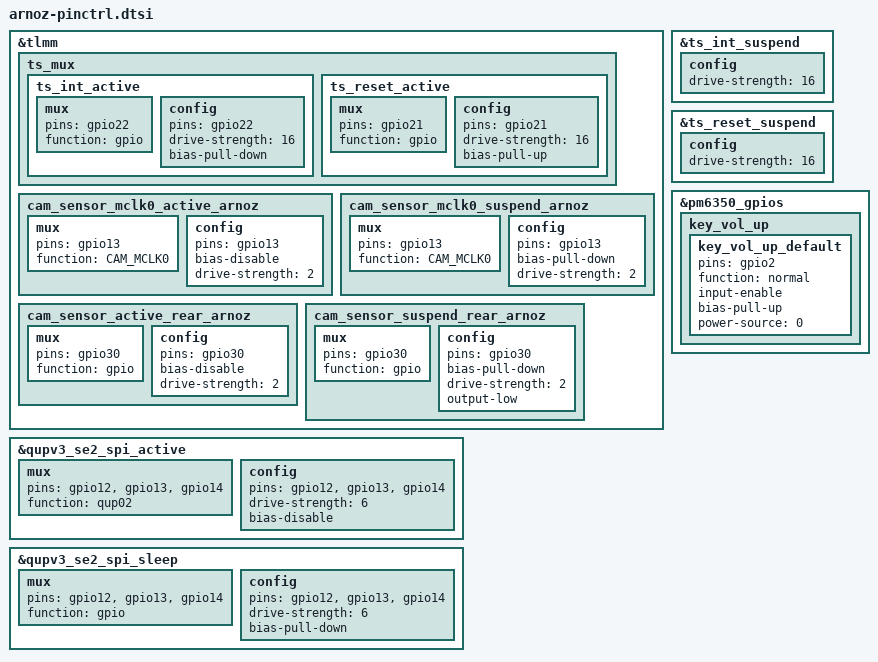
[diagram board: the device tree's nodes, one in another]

/* Touchscreen pinctrl - Himax HX83102 on qupv3_se2_spi */

/* Active states (not defined in lagoon-pinctrl.dtsi) */
&tlmm {
	ts_mux {
		ts_int_active: ts_int_active {
			mux {
				pins = "gpio22";
				function = "gpio";
			};
			config {
				pins = "gpio22";
				drive-strength = <16>;
				bias-pull-down;
			};
		};
		ts_reset_active: ts_reset_active {
			mux {
				pins = "gpio21";
				function = "gpio";
			};
			config {
				pins = "gpio21";
				drive-strength = <16>;
				bias-pull-up;
			};
		};
	};
};

/* Suspend states: override lagoon-pinctrl defaults (drive-strength 6 -> 16) */
&ts_int_suspend {
	config {
		drive-strength = <16>;
	};
};

&ts_reset_suspend {
	config {
		drive-strength = <16>;
	};
};

/* SPI CS pin mux for qupv3_se2 (touch chip select) */
&qupv3_se2_spi_active {
	mux {
		pins = "gpio12", "gpio13", "gpio14";
		function = "qup02";
	};
	config {
		pins = "gpio12", "gpio13", "gpio14";
		drive-strength = <6>;
		bias-disable;
	};
};

&qupv3_se2_spi_sleep {
	mux {
		pins = "gpio12", "gpio13", "gpio14";
		function = "gpio";
	};
	config {
		pins = "gpio12", "gpio13", "gpio14";
		drive-strength = <6>;
		bias-pull-down;
	};
};

/*
 * Camera pinctrl — override lagoon-default GPIOs to match J607F (arnoz) hardware.
 * Reference: PE Lito_MTP.dts / orchid.dts GPIO map:
 *   MCLK0 = gpio13, Rear_RESET = gpio30
 *   (lagoon-pinctrl.dtsi uses gpio29/gpio34 which is wrong for this board)
 */
&tlmm {
	cam_sensor_mclk0_active_arnoz: cam_sensor_mclk0_active_arnoz {
		mux {
			pins = "gpio13";
			function = "CAM_MCLK0";
		};
		config {
			pins = "gpio13";
			bias-disable;
			drive-strength = <2>;
		};
	};

	cam_sensor_mclk0_suspend_arnoz: cam_sensor_mclk0_suspend_arnoz {
		mux {
			pins = "gpio13";
			function = "CAM_MCLK0";
		};
		config {
			pins = "gpio13";
			bias-pull-down;
			drive-strength = <2>;
		};
	};

	cam_sensor_active_rear_arnoz: cam_sensor_active_rear_arnoz {
		mux {
			pins = "gpio30";
			function = "gpio";
		};
		config {
			pins = "gpio30";
			bias-disable;
			drive-strength = <2>;
		};
	};

	cam_sensor_suspend_rear_arnoz: cam_sensor_suspend_rear_arnoz {
		mux {
			pins = "gpio30";
			function = "gpio";
		};
		config {
			pins = "gpio30";
			bias-pull-down;
			drive-strength = <2>;
			output-low;
		};
	};
};

/* Volume up key - pm6350 GPIO 2 */
&pm6350_gpios {
	key_vol_up {
		key_vol_up_default: key_vol_up_default {
			pins = "gpio2";
			function = "normal";
			input-enable;
			bias-pull-up;
			power-source = <0>;
		};
	};
};
